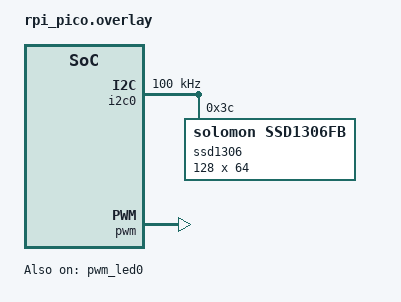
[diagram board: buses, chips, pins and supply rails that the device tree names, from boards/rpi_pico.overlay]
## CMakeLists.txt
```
# SPDX-License-Identifier: Apache-2.0

cmake_minimum_required(VERSION 3.20.0)
find_package(Zephyr REQUIRED HINTS $ENV{ZEPHYR_BASE})
project(zephyr_ssd1306)

target_sources(app PRIVATE src/main.c)
```

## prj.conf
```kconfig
CONFIG_I2C=y
CONFIG_DISPLAY=y
CONFIG_SSD1306=y
CONFIG_SSD1306_DEFAULT=y
CONFIG_SSD1306_DEFAULT_CONTRAST=128
CONFIG_LOG=y
CONFIG_CHARACTER_FRAMEBUFFER=y

CONFIG_STDOUT_CONSOLE=y

CONFIG_HEAP_MEM_POOL_SIZE=16384

CONFIG_DISPLAY=y

CONFIG_LOG=y

CONFIG_CFB_LOG_LEVEL_DBG=y
CONFIG_CHARACTER_FRAMEBUFFER=y
```

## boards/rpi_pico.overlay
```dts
#include "rpi_pico-pinctrl.dtsi"

/ {
pwm_leds {
		compatible = "pwm-leds";
		status = "disabled";
		pwm_led1: pwm_led_1 {
			pwms = <&pwm 7 PWM_MSEC(20) PWM_POLARITY_NORMAL>;
			label = "PWM_LED";
		};
	};

	aliases {
		pwm-led1 = &pwm_led1;
	};
};


&i2c0 {
	clock-frequency = <I2C_BITRATE_STANDARD>;
	status = "okay";
	pinctrl-0 = <&i2c0_default>;
	pinctrl-names = "default";

	ssd1306: ssd1306@3c {
      	       compatible = "solomon,ssd1306fb";
	       reg = <0x3c>;
	       height = <64>;
	       width = <128>;
	       segment-offset = <0>;
	       page-offset = <0>;
	       display-offset = <0>;
	       multiplex-ratio = <63>;
	       prechargep = <0x22>;
	       com-invdir;
	       segment-remap;
      };
};


&pwm_led0 {
	status = "okay";
};

&pwm {
	status = "okay";

	pinctrl-0 = <&pwm_chn_used>;

	// for pwm chanel 3 A and B

	divider-frac-3 = <15>;
	divider-int-3 = <255>;
	
	// for pwm chanel 4 A and B
	
	divider-frac-4 = <15>;
	divider-int-4 = <255>;
};
```

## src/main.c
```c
#include <stdint.h>
#include <zephyr/device.h>
#include <zephyr/kernel.h>
#include <zephyr/drivers/display.h>
#include <zephyr/logging/log.h>

#include "Logo_b.h"

#define DISPLAY_BUFFER_PITCH 128

LOG_MODULE_REGISTER(display);

static const struct device *display = DEVICE_DT_GET(DT_NODELABEL(ssd1306));

void main(void)
{
  if (display == NULL) {
    LOG_ERR("device pointer is NULL");
    return;
  }

  if (!device_is_ready(display)) {
    LOG_ERR("display device is not ready");
    return;
  }

  struct display_capabilities capabilities;
  display_get_capabilities(display, &capabilities);

  const uint16_t x_res = capabilities.x_resolution;
  const uint16_t y_res = capabilities.y_resolution;

  LOG_INF("x_resolution: %d", x_res);
  LOG_INF("y_resolution: %d", y_res);
  LOG_INF("supported pixel formats: %d", capabilities.supported_pixel_formats);
  LOG_INF("screen_info: %d", capabilities.screen_info);
  LOG_INF("current_pixel_format: %d", capabilities.current_pixel_format);
  LOG_INF("current_orientation: %d", capabilities.current_orientation);
	 
  const struct display_buffer_descriptor buf_desc = {
    .width = x_res,
    .height = y_res,
    .buf_size = x_res * y_res,
    .pitch = DISPLAY_BUFFER_PITCH
  };

  if (display_write(display, 0, 0, &buf_desc, buf) != 0) {
    LOG_ERR("could not write to display");
  }

  if (display_set_contrast(display, 0) != 0) {
    LOG_ERR("could not set display contrast");
  }
  size_t ms_sleep = 5;

  while (true) {
    // Increase brightness
    for (size_t i = 0; i < 255; i++) {
      display_set_contrast(display, i);
      k_sleep(K_MSEC(ms_sleep));
    }

    // Decrease brightness
    for (size_t i = 255; i > 0; i--) {
      display_set_contrast(display, i);
      k_sleep(K_MSEC(ms_sleep));
    }
  }
}
```

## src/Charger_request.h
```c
uint8_t buf[1024] = {
0xff, 0xff, 0xff, 0xff, 0xff, 0xff, 0xff, 0xff, 0xff, 0xff, 0xff, 0xff, 0xff, 0xff, 0xff, 0xff, 
0xff, 0xff, 0xff, 0xff, 0xff, 0xff, 0xff, 0xff, 0xff, 0xff, 0xff, 0xff, 0xff, 0xff, 0xff, 0xff, 
0xff, 0xff, 0xff, 0xff, 0xff, 0xff, 0xff, 0xff, 0xff, 0xff, 0xff, 0xff, 0xff, 0xff, 0xff, 0xff, 
0xff, 0xff, 0xff, 0xff, 0xff, 0xff, 0xff, 0xff, 0xff, 0xff, 0xff, 0xff, 0xff, 0xff, 0xff, 0xff, 
0xff, 0xff, 0xff, 0xff, 0xff, 0xff, 0xff, 0xff, 0xff, 0xff, 0xff, 0xff, 0xff, 0xff, 0xff, 0xff, 
0xff, 0xff, 0xff, 0xff, 0xff, 0xff, 0xff, 0xff, 0xff, 0xff, 0xff, 0xff, 0xff, 0xff, 0xff, 0xff, 
0xff, 0xff, 0xff, 0xff, 0xff, 0xff, 0xff, 0xff, 0xff, 0xff, 0xff, 0xff, 0xff, 0xff, 0xff, 0xff, 
0xff, 0xff, 0xff, 0xff, 0xff, 0xff, 0xff, 0xff, 0xff, 0xff, 0xff, 0xff, 0xff, 0xff, 0xff, 0xff, 
0xff, 0xff, 0xff, 0xff, 0xff, 0xff, 0xff, 0xff, 0xff, 0xff, 0xff, 0xff, 0x3f, 0x0f, 0x87, 0xe3, 
0xf3, 0xf9, 0xf9, 0xf9, 0xf9, 0xf9, 0xf9, 0xf9, 0xff, 0xff, 0xff, 0xff, 0x7f, 0x3f, 0x3f, 0x3f, 
0x3f, 0x3f, 0x7f, 0xff, 0xff, 0xff, 0xff, 0xff, 0x3f, 0x3f, 0x7f, 0x7f, 0x3f, 0x3f, 0x3f, 0x3f, 
0x7f, 0xff, 0xff, 0xff, 0xff, 0xff, 0xff, 0x7f, 0x7f, 0x3f, 0xbf, 0x3f, 0x3f, 0x7f, 0xff, 0xff, 
0xff, 0xff, 0xff, 0xff, 0x7f, 0x7f, 0x3f, 0x3f, 0x3f, 0x3f, 0x3f, 0xff, 0x3f, 0x3f, 0x07, 0x07, 
0x3f, 0x3f, 0x3f, 0xff, 0xff, 0xff, 0xff, 0xff, 0x7f, 0x3f, 0x3f, 0xbf, 0x3f, 0x7f, 0x7f, 0xff, 
0xff, 0xff, 0xff, 0xff, 0xff, 0xff, 0xff, 0xff, 0xff, 0x7f, 0x7f, 0x3f, 0xbf, 0x3f, 0x3f, 0x7f, 
0xff, 0xff, 0xff, 0xff, 0x00, 0x00, 0xff, 0xff, 0xff, 0xff, 0xff, 0xff, 0xff, 0xff, 0xff, 0xff, 
0xff, 0xff, 0xff, 0xff, 0xff, 0xff, 0xff, 0xff, 0xff, 0xff, 0xff, 0xff, 0xe0, 0x80, 0x1f, 0x3f, 
0x7f, 0xff, 0xff, 0xff, 0xff, 0xff, 0xff, 0xff, 0xff, 0xff, 0x81, 0x00, 0x3c, 0xff, 0xff, 0xff, 
0xff, 0xff, 0x3c, 0x00, 0x81, 0xff, 0xff, 0xff, 0x00, 0x00, 0xfe, 0xff, 0xff, 0xff, 0xff, 0xfe, 
0x00, 0x00, 0xff, 0xff, 0xff, 0x83, 0x00, 0x76, 0xf7, 0xf7, 0xf7, 0xf7, 0xf7, 0xf6, 0xf0, 0xf1, 
0xff, 0xff, 0x81, 0x00, 0x3c, 0x7e, 0xff, 0xff, 0xff, 0xff, 0xff, 0xff, 0xff, 0xff, 0x00, 0x00, 
0xff, 0xff, 0xff, 0xff, 0xff, 0xff, 0x83, 0x00, 0x76, 0xf7, 0xf7, 0xf7, 0xf7, 0xf6, 0xf0, 0xf1, 
0xff, 0xff, 0xff, 0xff, 0xff, 0xff, 0xff, 0x83, 0x00, 0x76, 0xf7, 0xf7, 0xf7, 0xf7, 0xf7, 0xf6, 
0xf0, 0xf1, 0xff, 0xff, 0x00, 0x00, 0xff, 0xff, 0xff, 0xff, 0xff, 0xff, 0xff, 0xff, 0xff, 0xff, 
0xff, 0xff, 0xff, 0xff, 0xff, 0xff, 0xff, 0xff, 0xff, 0xff, 0xff, 0xff, 0xff, 0xff, 0xff, 0xfe, 
0xfe, 0xfc, 0xfc, 0xfc, 0xfc, 0xfc, 0xfc, 0xfc, 0xff, 0xff, 0xff, 0xff, 0xfe, 0xfc, 0xfc, 0xfc, 
0xfc, 0xfc, 0xfe, 0xff, 0xff, 0xff, 0xff, 0xff, 0xfc, 0xfc, 0xff, 0xff, 0xff, 0xff, 0xff, 0xff, 
0xfc, 0xfc, 0xff, 0xff, 0xff, 0xff, 0xff, 0xfe, 0xfc, 0xfc, 0xfc, 0xfc, 0xfc, 0xfc, 0xfc, 0xff, 
0xff, 0xff, 0xff, 0xff, 0xfe, 0xfc, 0xfc, 0xfc, 0xfc, 0xfc, 0xfc, 0xff, 0xff, 0xff, 0xff, 0xfc, 
0xfc, 0xfc, 0xfc, 0xff, 0xff, 0xff, 0xff, 0xff, 0xfe, 0xfc, 0xfc, 0xfc, 0xfc, 0xfc, 0xfc, 0xff, 
0xff, 0xff, 0xff, 0xff, 0xff, 0xff, 0xff, 0xff, 0xff, 0xfe, 0xfc, 0xfc, 0xfc, 0xfc, 0xfc, 0xfc, 
0xfc, 0xff, 0xff, 0xff, 0xfc, 0xfc, 0xff, 0xff, 0xff, 0xff, 0xff, 0xff, 0xff, 0xff, 0xff, 0xff, 
0xff, 0xff, 0xff, 0xff, 0xff, 0xff, 0xff, 0xff, 0xff, 0xff, 0xff, 0xff, 0xff, 0xff, 0xff, 0xff, 
0xff, 0x3f, 0x0f, 0x87, 0xe3, 0xf3, 0xf9, 0xf9, 0xf9, 0xf9, 0xf9, 0xf9, 0xf9, 0xff, 0xff, 0xff, 
0x7f, 0x3f, 0x3f, 0x3f, 0x3f, 0x3f, 0x7f, 0xff, 0xff, 0xff, 0xff, 0xff, 0x3f, 0x3f, 0x7f, 0x7f, 
0x3f, 0x3f, 0xff, 0xff, 0xff, 0x7f, 0x3f, 0x3f, 0x3f, 0x3f, 0x3f, 0x7f, 0x3f, 0x3f, 0xff, 0xff, 
0xff, 0xff, 0x7f, 0x3f, 0x3f, 0x3f, 0x3f, 0x3f, 0x7f, 0xff, 0xff, 0xff, 0xff, 0xff, 0xff, 0x7f, 
0x3f, 0x3f, 0x3f, 0x3f, 0x7f, 0x7f, 0x00, 0x00, 0xff, 0xff, 0xff, 0xff, 0xff, 0x7f, 0x7f, 0x3f, 
0x3f, 0x3f, 0x3f, 0x7f, 0x7f, 0xff, 0xff, 0xff, 0xff, 0xff, 0x3f, 0x3f, 0x7f, 0x7f, 0x3f, 0x3f, 
0xff, 0xff, 0xff, 0xff, 0xff, 0xff, 0xff, 0xff, 0xff, 0xff, 0xff, 0xff, 0xff, 0xff, 0xff, 0xff, 
0xff, 0xff, 0xff, 0xff, 0xff, 0xff, 0xff, 0xff, 0xff, 0xff, 0xff, 0xff, 0xff, 0xff, 0xff, 0xff, 
0xff, 0xe0, 0x80, 0x1f, 0x3f, 0x7f, 0xff, 0xff, 0xff, 0xff, 0xff, 0xff, 0xff, 0xff, 0xff, 0x1f, 
0x0f, 0xe7, 0xf7, 0xf7, 0xf7, 0x76, 0x00, 0x00, 0xff, 0xff, 0xff, 0xff, 0x00, 0x00, 0xfc, 0xff, 
0xff, 0xff, 0xff, 0x83, 0x00, 0x3c, 0x7e, 0xff, 0xff, 0xff, 0xff, 0x7e, 0x00, 0x00, 0xff, 0xff, 
0xff, 0x1f, 0x0f, 0xe7, 0xf7, 0xf7, 0xf7, 0x76, 0x00, 0x00, 0xff, 0xff, 0xff, 0x83, 0x00, 0x3c, 
0x7e, 0xff, 0xff, 0xff, 0xff, 0x7e, 0x00, 0x00, 0xff, 0xff, 0xff, 0xc3, 0x00, 0x3c, 0x7e, 0xff, 
0xff, 0xff, 0xff, 0x7e, 0x3c, 0x00, 0xc3, 0xff, 0xff, 0xff, 0x00, 0x00, 0xfc, 0xff, 0xff, 0xff, 
0xff, 0xff, 0xff, 0xff, 0xff, 0xff, 0xff, 0xff, 0xff, 0xff, 0xff, 0xff, 0xff, 0xff, 0xff, 0xff, 
0xff, 0xff, 0xff, 0xff, 0xff, 0xff, 0xff, 0xff, 0xff, 0xff, 0xff, 0xff, 0xff, 0xff, 0xff, 0xff, 
0xff, 0xff, 0xff, 0xff, 0xfe, 0xfe, 0xfc, 0xfc, 0xfc, 0xfc, 0xfc, 0xfc, 0xfc, 0xff, 0xff, 0xfe, 
0xfe, 0xfc, 0xfc, 0xfc, 0xfe, 0xfe, 0xfc, 0xfc, 0xff, 0xff, 0xff, 0xff, 0xfc, 0xfc, 0xff, 0xff, 
0xff, 0xff, 0xff, 0xff, 0xdf, 0x9e, 0x9c, 0x9c, 0x9c, 0x9c, 0x9e, 0xce, 0xc0, 0xf0, 0xff, 0xff, 
0xff, 0xfe, 0xfe, 0xfc, 0xfc, 0xfc, 0xfe, 0xfe, 0xfc, 0xfc, 0xff, 0xff, 0xff, 0xff, 0xff, 0xfe, 
0xfc, 0xfc, 0xfc, 0xfc, 0xfe, 0xfe, 0xfc, 0xfc, 0xff, 0xff, 0xff, 0xff, 0xff, 0xfe, 0xfe, 0xfc, 
0xfc, 0xfc, 0xfc, 0xfe, 0xfe, 0xff, 0xff, 0xff, 0xff, 0xff, 0xfc, 0xfc, 0xff, 0xff, 0xff, 0xff, 
0xff, 0xff, 0xff, 0xff, 0xff, 0xff, 0xff, 0xff, 0xff, 0xff, 0xff, 0xff, 0xff, 0xff, 0xff, 0xff, 
0xff, 0xff, 0xff, 0xff, 0xff, 0xff, 0xff, 0xff, 0xff, 0xff, 0xff, 0xff, 0xff, 0xff, 0xff, 0xff, 
0xff, 0xff, 0xff, 0xff, 0xff, 0xff, 0xff, 0xff, 0xff, 0xff, 0xff, 0xff, 0xff, 0xff, 0xff, 0xff, 
0xff, 0xff, 0xff, 0xff, 0xff, 0xff, 0xff, 0xff, 0xff, 0xff, 0xff, 0xff, 0xff, 0xff, 0xff, 0xff, 
0xff, 0xff, 0xff, 0xff, 0xff, 0xff, 0xff, 0xff, 0xff, 0xff, 0xff, 0xff, 0xff, 0xff, 0xff, 0xff, 
0xff, 0xff, 0xff, 0xff, 0xff, 0xff, 0xff, 0xff, 0xff, 0xff, 0xff, 0xff, 0xff, 0xff, 0xff, 0xff, 
0xff, 0xff, 0xff, 0xff, 0xff, 0xff, 0xff, 0xff, 0xff, 0xff, 0xff, 0xff, 0xff, 0xff, 0xff, 0xff, 
0xff, 0xff, 0xff, 0xff, 0xff, 0xff, 0xff, 0xff, 0xff, 0xff, 0xff, 0xff, 0xff, 0xff, 0xff, 0xff, 
0xff, 0xff, 0xff, 0xff, 0xff, 0xff, 0xff, 0xff, 0xff, 0xff, 0xff, 0xff, 0xff, 0xff, 0xff, 0xff
};
```

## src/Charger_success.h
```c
uint8_t buf[1024] = {
0xff, 0xff, 0xff, 0xff, 0xff, 0xff, 0xff, 0xff, 0xff, 0xff, 0xff, 0xff, 0xff, 0xff, 0xff, 0xff, 
0xff, 0xff, 0xff, 0xff, 0xff, 0xff, 0xff, 0xff, 0xff, 0xff, 0xff, 0xff, 0xff, 0xff, 0xff, 0xff, 
0xff, 0xff, 0xff, 0xff, 0xff, 0xff, 0xff, 0xff, 0xff, 0xff, 0xff, 0xff, 0xff, 0xff, 0xff, 0xff, 
0xff, 0xff, 0xff, 0xff, 0xff, 0xff, 0xff, 0xff, 0xff, 0xff, 0xff, 0xff, 0xff, 0xff, 0xff, 0xff, 
0xff, 0xff, 0xff, 0xff, 0xff, 0xff, 0xff, 0xff, 0xff, 0xff, 0xff, 0xff, 0xff, 0xff, 0xff, 0xff, 
0xff, 0xff, 0xff, 0xff, 0xff, 0xff, 0xff, 0xff, 0xff, 0xff, 0xff, 0xff, 0xff, 0xff, 0xff, 0xff, 
0xff, 0xff, 0xff, 0xff, 0xff, 0xff, 0xff, 0xff, 0xff, 0xff, 0xff, 0xff, 0xff, 0xff, 0xff, 0xff, 
0xff, 0xff, 0xff, 0xff, 0xff, 0xff, 0xff, 0xff, 0xff, 0xff, 0xff, 0xff, 0xff, 0xff, 0xff, 0xff, 
0xff, 0xff, 0xff, 0xff, 0x7f, 0x1f, 0x0f, 0xc7, 0xe7, 0xf3, 0xf3, 0xf3, 0xf3, 0xf3, 0xf3, 0xf3, 
0xff, 0xff, 0xff, 0x7f, 0x7f, 0x7f, 0x7f, 0x7f, 0xff, 0xff, 0xff, 0xff, 0xff, 0xff, 0x7f, 0x7f, 
0xff, 0xff, 0x7f, 0x7f, 0xff, 0xff, 0xff, 0xff, 0xff, 0x7f, 0x7f, 0x7f, 0x7f, 0xff, 0xff, 0x7f, 
0x7f, 0xff, 0xff, 0xff, 0xff, 0x7f, 0x7f, 0x7f, 0x7f, 0x7f, 0xff, 0xff, 0xff, 0xff, 0xff, 0xff, 
0xff, 0xff, 0xff, 0x7f, 0x7f, 0x7f, 0x7f, 0xff, 0xff, 0x01, 0x01, 0xff, 0xff, 0xff, 0xff, 0xff, 
0xff, 0x7f, 0x7f, 0x7f, 0x7f, 0x7f, 0xff, 0xff, 0xff, 0xff, 0xff, 0xff, 0x7f, 0x7f, 0xff, 0xff, 
0x7f, 0x7f, 0xff, 0xff, 0xff, 0xff, 0xff, 0xff, 0xff, 0xff, 0xff, 0xff, 0xff, 0xff, 0xff, 0xff, 
0xff, 0xff, 0xff, 0xff, 0xff, 0x7f, 0x3f, 0x1f, 0x0f, 0x0f, 0x9f, 0xff, 0xff, 0xff, 0xff, 0xff, 
0xff, 0xff, 0xff, 0xff, 0xc0, 0x00, 0x3f, 0x7f, 0xff, 0xff, 0xff, 0xff, 0xff, 0xff, 0xff, 0xff, 
0xff, 0x3f, 0x1e, 0xce, 0xce, 0xee, 0xee, 0xee, 0xe4, 0x00, 0x01, 0xff, 0xff, 0xff, 0x00, 0x00, 
0xf9, 0xfc, 0xfe, 0xfe, 0xff, 0xff, 0x03, 0x01, 0x78, 0xfe, 0xfe, 0xfe, 0xfe, 0xfe, 0x7c, 0x00, 
0x00, 0xff, 0xff, 0x3f, 0x1e, 0xce, 0xce, 0xee, 0xee, 0xee, 0xe4, 0x00, 0x01, 0xff, 0xff, 0xff, 
0x03, 0x01, 0xf8, 0xfe, 0xfe, 0xfe, 0xfe, 0xfe, 0xf8, 0x00, 0x00, 0xff, 0xff, 0xff, 0x03, 0x01, 
0x78, 0xfe, 0xfe, 0xfe, 0xfe, 0xfe, 0x78, 0x01, 0x03, 0xff, 0xff, 0xff, 0x00, 0x00, 0xf9, 0xfc, 
0xfe, 0xfe, 0xff, 0xff, 0xff, 0xff, 0xff, 0xff, 0xe7, 0xc3, 0x83, 0x03, 0x07, 0x0f, 0x1f, 0x1f, 
0x0f, 0x07, 0x83, 0xc1, 0xe0, 0xf0, 0xf8, 0xfc, 0xfe, 0xff, 0xff, 0xff, 0xff, 0xff, 0xff, 0xff, 
0xff, 0xff, 0xff, 0xff, 0xff, 0xff, 0xfe, 0xfc, 0xfc, 0xf9, 0xf9, 0xf9, 0xf9, 0xf9, 0xf9, 0xf9, 
0xff, 0xfe, 0xfc, 0xf8, 0xf9, 0xf9, 0xf9, 0xfd, 0xfc, 0xf8, 0xf8, 0xff, 0xff, 0xff, 0xf8, 0xf8, 
0xff, 0xff, 0xff, 0xff, 0xff, 0xff, 0xff, 0xbc, 0x3c, 0x39, 0x39, 0x39, 0x39, 0x3d, 0x8c, 0xc0, 
0xe0, 0xff, 0xff, 0xfe, 0xfc, 0xf8, 0xf9, 0xf9, 0xf9, 0xfd, 0xfc, 0xf8, 0xf8, 0xff, 0xff, 0xff, 
0xff, 0xfc, 0xfc, 0xf9, 0xf9, 0xf9, 0xf9, 0xfd, 0xfe, 0xf8, 0xf8, 0xff, 0xff, 0xff, 0xff, 0xfe, 
0xfc, 0xf9, 0xf9, 0xf9, 0xf9, 0xf9, 0xfc, 0xfe, 0xff, 0xff, 0xff, 0xff, 0xf8, 0xf8, 0xff, 0xff, 
0xff, 0xff, 0xff, 0xff, 0xff, 0xff, 0xff, 0xff, 0xff, 0xff, 0xff, 0xff, 0xfe, 0xfc, 0xf8, 0xfc, 
0xfe, 0xff, 0xff, 0xff, 0xff, 0xff, 0xff, 0xff, 0xff, 0xff, 0xff, 0xff, 0xff, 0xff, 0xff, 0xff, 
0xff, 0xff, 0xff, 0xff, 0xff, 0x7f, 0x3f, 0x1f, 0x9f, 0xcf, 0xcf, 0xcf, 0xcf, 0xcf, 0xcf, 0xcf, 
0xff, 0xff, 0xff, 0xff, 0xff, 0xff, 0xff, 0xff, 0xff, 0xff, 0xff, 0xff, 0xff, 0xff, 0xff, 0xff, 
0xff, 0xff, 0xff, 0xff, 0xff, 0xff, 0xff, 0xff, 0xff, 0xff, 0xff, 0xff, 0xff, 0xff, 0xff, 0xff, 
0xff, 0xff, 0xff, 0xff, 0xff, 0xff, 0xff, 0xff, 0xff, 0xff, 0xff, 0xff, 0xff, 0xff, 0xff, 0xff, 
0xff, 0xff, 0xff, 0xff, 0xff, 0xff, 0xff, 0x3f, 0x3f, 0xff, 0xff, 0xff, 0xff, 0xff, 0xff, 0xff, 
0xff, 0xff, 0xff, 0xff, 0xff, 0xff, 0xff, 0xff, 0xff, 0xff, 0xff, 0xff, 0xff, 0xff, 0xff, 0xff, 
0xff, 0xff, 0xff, 0x07, 0x07, 0xff, 0xff, 0xff, 0xff, 0xff, 0xff, 0xff, 0xff, 0xff, 0xff, 0xff, 
0xff, 0xff, 0xff, 0xff, 0xff, 0xff, 0xff, 0xff, 0xff, 0xff, 0xff, 0xff, 0xff, 0xff, 0xff, 0xff, 
0xff, 0xff, 0xff, 0xff, 0x01, 0x00, 0xfc, 0xff, 0xff, 0xff, 0xff, 0xff, 0xff, 0xff, 0xff, 0xff, 
0xff, 0xff, 0x0f, 0x07, 0xe3, 0xf9, 0xf9, 0xf9, 0xf9, 0xf9, 0xe3, 0x07, 0x0f, 0xff, 0xff, 0xff, 
0x01, 0x01, 0xe7, 0xfb, 0xf9, 0xf9, 0xf9, 0xf9, 0xe1, 0x03, 0x0f, 0xff, 0xff, 0x1f, 0x07, 0xb3, 
0xbb, 0xb9, 0xbd, 0xb9, 0xb9, 0xb3, 0x87, 0x8f, 0xff, 0xff, 0x1f, 0x07, 0xe3, 0xf3, 0xf9, 0xf9, 
0xf9, 0xf9, 0xf9, 0xff, 0xff, 0xf9, 0xf9, 0x00, 0x00, 0xf9, 0xf9, 0xf9, 0xff, 0xff, 0x7b, 0x39, 
0x39, 0xb9, 0xb9, 0xb9, 0x93, 0x03, 0x07, 0xff, 0xff, 0xff, 0x0f, 0x07, 0xe3, 0xf9, 0xf9, 0xf9, 
0xf9, 0xfb, 0xe3, 0x00, 0x00, 0xff, 0xff, 0xff, 0x0f, 0x07, 0xe3, 0xf9, 0xf9, 0xf9, 0xf9, 0xf9, 
0xe3, 0x07, 0x0f, 0xff, 0xff, 0xff, 0xff, 0xff, 0xff, 0xff, 0xff, 0xff, 0xff, 0xff, 0xff, 0xff, 
0xff, 0xff, 0xff, 0xff, 0xff, 0xfc, 0xf8, 0xf1, 0xf3, 0xe7, 0xe7, 0xe7, 0xe7, 0xe7, 0xe7, 0xe7, 
0xff, 0xff, 0xfc, 0xf8, 0xf1, 0xe7, 0xe7, 0xe7, 0xe7, 0xe7, 0xf1, 0xf8, 0xfc, 0xff, 0xff, 0xff, 
0xe0, 0xe0, 0xff, 0xff, 0xff, 0xff, 0xff, 0xff, 0xff, 0xe0, 0xe0, 0xff, 0xff, 0xfc, 0xf8, 0xf3, 
0xe7, 0xe7, 0xe7, 0xe7, 0xe7, 0xe7, 0xe7, 0xff, 0xff, 0xff, 0xfe, 0xf8, 0xf1, 0xf3, 0xe7, 0xe7, 
0xe7, 0xe7, 0xe7, 0xff, 0xff, 0xff, 0xff, 0xf0, 0xe0, 0xe7, 0xe7, 0xe7, 0xff, 0xf8, 0xf0, 0xe3, 
0xe7, 0xe7, 0xe7, 0xf7, 0xf3, 0xe0, 0xe0, 0xff, 0xff, 0xff, 0xfc, 0xf0, 0xf3, 0xe7, 0xe7, 0xe7, 
0xe7, 0xf7, 0xfb, 0xe0, 0xe0, 0xff, 0xff, 0xff, 0xfc, 0xf8, 0xf1, 0xe7, 0xe7, 0xe7, 0xe7, 0xe7, 
0xf1, 0xf8, 0xfc, 0xff, 0xff, 0xff, 0xff, 0xff, 0xff, 0xff, 0xff, 0xff, 0xff, 0xff, 0xff, 0xff, 
0xff, 0xff, 0xff, 0xff, 0xff, 0xff, 0xff, 0xff, 0xff, 0xff, 0xff, 0xff, 0xff, 0xff, 0xff, 0xff, 
0xff, 0xff, 0xff, 0xff, 0xff, 0xff, 0xff, 0xff, 0xff, 0xff, 0xff, 0xff, 0xff, 0xff, 0xff, 0xff, 
0xff, 0xff, 0xff, 0xff, 0xff, 0xff, 0xff, 0xff, 0xff, 0xff, 0xff, 0xff, 0xff, 0xff, 0xff, 0xff, 
0xff, 0xff, 0xff, 0xff, 0xff, 0xff, 0xff, 0xff, 0xff, 0xff, 0xff, 0xff, 0xff, 0xff, 0xff, 0xff, 
0xff, 0xff, 0xff, 0xff, 0xff, 0xff, 0xff, 0xff, 0xff, 0xff, 0xff, 0xff, 0xff, 0xff, 0xff, 0xff, 
0xff, 0xff, 0xff, 0xff, 0xff, 0xff, 0xff, 0xff, 0xff, 0xff, 0xff, 0xff, 0xff, 0xff, 0xff, 0xff, 
0xff, 0xff, 0xff, 0xff, 0xff, 0xff, 0xff, 0xff, 0xff, 0xff, 0xff, 0xff, 0xff, 0xff, 0xff, 0xff, 
0xff, 0xff, 0xff, 0xff, 0xff, 0xff, 0xff, 0xff, 0xff, 0xff, 0xff, 0xff, 0xff, 0xff, 0xff, 0xff
};
```

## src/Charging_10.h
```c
uint8_t buf[1024] = {
0xff, 0xff, 0xff, 0xff, 0xff, 0xff, 0xff, 0xff, 0xff, 0xff, 0xff, 0xff, 0xff, 0xff, 0xff, 0xff, 
0xff, 0x7f, 0x7f, 0x7f, 0x7f, 0x7f, 0x7f, 0x7f, 0xff, 0xff, 0xff, 0xff, 0xff, 0xff, 0xff, 0xff, 
0xff, 0xff, 0xff, 0xff, 0xff, 0xff, 0xff, 0xff, 0xff, 0xff, 0xff, 0xff, 0xff, 0xff, 0xff, 0xff, 
0xff, 0xff, 0xff, 0xff, 0xff, 0xff, 0xff, 0xff, 0xff, 0xff, 0xff, 0xff, 0xff, 0xff, 0xff, 0xff, 
0xff, 0xff, 0xff, 0xff, 0xff, 0xff, 0xff, 0xff, 0xff, 0xff, 0xff, 0xff, 0xff, 0xff, 0xff, 0xff, 
0xff, 0xff, 0xff, 0xff, 0xff, 0xff, 0xff, 0xff, 0xff, 0xff, 0xff, 0xff, 0xff, 0xff, 0xff, 0x3f, 
0x3f, 0xff, 0xff, 0xff, 0xff, 0xff, 0xff, 0xff, 0xff, 0xff, 0xff, 0xff, 0xff, 0xff, 0xff, 0xff, 
0xff, 0xff, 0xff, 0xff, 0xff, 0xff, 0xff, 0xff, 0xff, 0xff, 0xff, 0xff, 0xff, 0xff, 0xff, 0xff, 
0xff, 0xff, 0xff, 0xff, 0xff, 0xff, 0xff, 0xff, 0xff, 0xff, 0xff, 0xff, 0x0f, 0x03, 0xe1, 0xf8, 
0xfc, 0xfe, 0xfe, 0xfe, 0xfe, 0xfe, 0xfe, 0xfe, 0xff, 0xff, 0xdf, 0xcf, 0xcf, 0xcf, 0xcf, 0xcf, 
0x9f, 0x1f, 0x3f, 0xff, 0xff, 0xff, 0x0f, 0x0f, 0x3f, 0x9f, 0xcf, 0xcf, 0xff, 0xff, 0x7f, 0x3f, 
0x1f, 0xcf, 0xcf, 0xcf, 0xcf, 0xdf, 0x9f, 0x0f, 0x0f, 0xff, 0xff, 0xff, 0xdf, 0xcf, 0xcf, 0xcf, 
0xcf, 0xcf, 0x9f, 0x1f, 0x3f, 0xff, 0xff, 0xff, 0x0f, 0x0f, 0x3f, 0xdf, 0xcf, 0xcf, 0xcf, 0xcf, 
0x0f, 0x1f, 0x7f, 0xff, 0xff, 0xff, 0x7f, 0x3f, 0x1f, 0xcf, 0xcf, 0xcf, 0xcf, 0xdf, 0x1f, 0x00, 
0x00, 0xff, 0xff, 0xff, 0x7f, 0x3f, 0x1f, 0xcf, 0xcf, 0xcf, 0xcf, 0xcf, 0x1f, 0x3f, 0x7f, 0xff, 
0xff, 0xff, 0xff, 0xff, 0xff, 0xff, 0xff, 0xff, 0xff, 0xff, 0xff, 0xff, 0xff, 0xff, 0xff, 0xff, 
0xff, 0xff, 0xff, 0xff, 0xff, 0xff, 0xff, 0xff, 0xff, 0xff, 0xff, 0xff, 0xf8, 0xe0, 0xc7, 0x8f, 
0x9f, 0x3f, 0x3f, 0x3f, 0x3f, 0x3f, 0x3f, 0x3f, 0xff, 0xc7, 0x83, 0x19, 0x39, 0x3d, 0x3d, 0xbd, 
0x9c, 0x00, 0x00, 0xff, 0xff, 0xff, 0x00, 0x00, 0xff, 0xff, 0xff, 0xff, 0xff, 0xff, 0xe0, 0x80, 
0x8f, 0x3f, 0x3f, 0x3f, 0x3f, 0xbf, 0x8f, 0x00, 0x00, 0xff, 0xff, 0xc7, 0x83, 0x19, 0x39, 0x3d, 
0x3d, 0xbd, 0x9c, 0x00, 0x00, 0xff, 0xff, 0xff, 0x00, 0x00, 0xff, 0xff, 0xff, 0xff, 0xff, 0xff, 
0xff, 0x00, 0x00, 0xff, 0xff, 0xff, 0xe0, 0x80, 0x9f, 0x3f, 0x3f, 0x3f, 0x3f, 0xbf, 0xdf, 0x00, 
0x00, 0xff, 0xff, 0xff, 0xe0, 0xc0, 0x8f, 0x3f, 0x3f, 0x3f, 0x3f, 0x3f, 0x8f, 0xc0, 0xe0, 0xff, 
0xff, 0xff, 0xff, 0xff, 0xff, 0xff, 0xff, 0xff, 0xff, 0xff, 0xff, 0xff, 0xff, 0xff, 0xff, 0xff, 
0xff, 0xff, 0xff, 0xff, 0xff, 0xff, 0xff, 0xff, 0xff, 0xff, 0xff, 0xff, 0xff, 0xff, 0xff, 0xff, 
0xff, 0xff, 0xff, 0xff, 0xff, 0xff, 0xff, 0xff, 0xff, 0xff, 0xff, 0xff, 0xff, 0xff, 0xff, 0xff, 
0xff, 0xff, 0xff, 0xff, 0xff, 0xff, 0xff, 0xff, 0xff, 0xff, 0xff, 0xff, 0xff, 0xff, 0xff, 0xf7, 
0xe7, 0xe7, 0xe7, 0xe7, 0xe7, 0xe7, 0xf1, 0xf8, 0xfc, 0xff, 0xff, 0xff, 0xff, 0xff, 0xff, 0xff, 
0xff, 0xff, 0xff, 0xff, 0xff, 0xff, 0xff, 0xff, 0xff, 0xff, 0xff, 0xff, 0xff, 0xff, 0xff, 0xff, 
0xff, 0xff, 0xff, 0xff, 0xff, 0xff, 0xff, 0xff, 0xff, 0xff, 0xff, 0xff, 0xff, 0xff, 0xff, 0xff, 
0xff, 0xff, 0xff, 0xff, 0xff, 0xff, 0xff, 0xff, 0xff, 0xff, 0xff, 0xff, 0xff, 0xff, 0xff, 0xff, 
0xff, 0xff, 0xff, 0xff, 0xff, 0xff, 0xff, 0xff, 0xff, 0xff, 0xff, 0xff, 0xff, 0xff, 0xff, 0xff, 
0xff, 0xff, 0xff, 0xff, 0xff, 0xff, 0xff, 0xff, 0xff, 0xff, 0xff, 0xff, 0xff, 0xff, 0xff, 0xff, 
0x3f, 0x1f, 0x0f, 0x07, 0x03, 0x83, 0xc1, 0xe1, 0xe1, 0xe1, 0xf1, 0xf1, 0xf0, 0xf0, 0xf0, 0xf0, 
0xf0, 0xf0, 0xf0, 0xf0, 0xf0, 0xf0, 0xf0, 0xf0, 0xf0, 0xf0, 0xf0, 0xf0, 0xf0, 0xf0, 0xf0, 0xf0, 
0xf0, 0xf0, 0xf0, 0xf0, 0xf0, 0xf0, 0xf0, 0xf0, 0xf0, 0xf0, 0xf0, 0xf0, 0xf0, 0xf0, 0xf0, 0xf0, 
0xf0, 0xf0, 0xf0, 0xf0, 0xf0, 0xf0, 0xf0, 0xf0, 0xf0, 0xf0, 0xf0, 0xf0, 0xf0, 0xf0, 0xf0, 0xf0, 
0xf0, 0xf0, 0xf0, 0xf0, 0xf0, 0xf0, 0xf0, 0xf0, 0xf0, 0xf0, 0xf0, 0xf0, 0xf0, 0xf0, 0xf0, 0xf0, 
0xf0, 0xf0, 0xf0, 0xf0, 0xf0, 0xf0, 0xe0, 0xe0, 0xe1, 0xc1, 0x81, 0x03, 0x07, 0x07, 0x1f, 0x3f, 
0x7f, 0xff, 0xff, 0xff, 0xff, 0xff, 0xff, 0xff, 0xff, 0xff, 0xff, 0xff, 0xff, 0xff, 0xff, 0xff, 
0xff, 0xff, 0xff, 0xff, 0xff, 0xff, 0xff, 0xff, 0xff, 0xff, 0xff, 0xff, 0xff, 0xff, 0x87, 0x00, 
0x00, 0x00, 0x00, 0xfe, 0xff, 0xff, 0xff, 0x87, 0x03, 0x01, 0x01, 0x01, 0x01, 0x01, 0x01, 0x01, 
0xff, 0xff, 0xff, 0xff, 0xff, 0xff, 0xff, 0xff, 0xff, 0xff, 0xff, 0xff, 0xff, 0xff, 0xff, 0xff, 
0xff, 0xff, 0xff, 0xff, 0xff, 0xff, 0xff, 0xff, 0xff, 0xff, 0xff, 0xff, 0xff, 0xff, 0xff, 0xff, 
0xff, 0xff, 0xff, 0xff, 0xff, 0xff, 0xff, 0xff, 0xff, 0xff, 0xff, 0xff, 0xff, 0xff, 0xff, 0xff, 
0xff, 0xff, 0xff, 0xff, 0xff, 0xff, 0xff, 0xff, 0xff, 0xff, 0xff, 0xff, 0xff, 0xff, 0xff, 0xff, 
0xff, 0xff, 0xff, 0xff, 0xff, 0xff, 0xff, 0xff, 0xff, 0xff, 0xff, 0xff, 0xfe, 0x00, 0x00, 0x00, 
0x00, 0x03, 0xff, 0xff, 0xff, 0xff, 0xff, 0xff, 0xff, 0xff, 0xff, 0xff, 0xff, 0xff, 0xff, 0xff, 
0xff, 0xff, 0xff, 0xff, 0xff, 0xff, 0xff, 0xff, 0xff, 0xff, 0xff, 0xff, 0xff, 0xff, 0xff, 0xfc, 
0xf0, 0xc0, 0x80, 0x81, 0x03, 0x07, 0x0f, 0x1f, 0x1f, 0x1e, 0x3e, 0x3e, 0x3e, 0x3e, 0x3e, 0x3e, 
0x3f, 0x3f, 0x3f, 0x3f, 0x3f, 0x3f, 0x3f, 0x3f, 0x3f, 0x3f, 0x3f, 0x3f, 0x3f, 0x3f, 0x3f, 0x3f, 
0x3f, 0x3f, 0x3f, 0x3f, 0x3f, 0x3f, 0x3f, 0x3f, 0x3f, 0x3f, 0x3f, 0x3f, 0x3f, 0x3f, 0x3f, 0x3f, 
0x3f, 0x3f, 0x3f, 0x3f, 0x3f, 0x3f, 0x3f, 0x3f, 0x3f, 0x3f, 0x3f, 0x3f, 0x3f, 0x3f, 0x3f, 0x3f, 
0x3f, 0x3f, 0x3f, 0x3f, 0x3f, 0x3f, 0x3f, 0x3f, 0x3f, 0x3f, 0x3f, 0x3f, 0x3f, 0x3f, 0x3f, 0x3f, 
0x3f, 0x3f, 0x3f, 0x3f, 0x3f, 0x3f, 0x3f, 0x1f, 0x1f, 0x0f, 0x0f, 0x07, 0x01, 0x80, 0xc0, 0xe0, 
0xf8, 0xff, 0xff, 0xff, 0xff, 0xff, 0xff, 0xff, 0xff, 0xff, 0xff, 0xff, 0xff, 0xff, 0xff, 0xff, 
0xff, 0xff, 0xff, 0xff, 0xff, 0xff, 0xff, 0xff, 0xff, 0xff, 0xff, 0xff, 0xff, 0xff, 0xff, 0xff, 
0xff, 0xff, 0xff, 0xff, 0xff, 0xfe, 0xfe, 0xfc, 0xfc, 0xfc, 0xfc, 0xfc, 0xfc, 0xfc, 0xfc, 0xfc, 
0xfc, 0xfc, 0xfc, 0xfc, 0xfc, 0xfc, 0xfc, 0xfc, 0xfc, 0xfc, 0xfc, 0xfc, 0xfc, 0xfc, 0xfc, 0xfc, 
0xfc, 0xfc, 0xfc, 0xfc, 0xfc, 0xfc, 0xfc, 0xfc, 0xfc, 0xfc, 0xfc, 0xfc, 0xfc, 0xfc, 0xfc, 0xfc, 
0xfc, 0xfc, 0xfc, 0xfc, 0xfc, 0xfc, 0xfc, 0xfc, 0xfc, 0xfc, 0xfc, 0xfc, 0xfc, 0xfc, 0xfc, 0xfc, 
0xfc, 0xfc, 0xfc, 0xfc, 0xfc, 0xfc, 0xfc, 0xfc, 0xfc, 0xfc, 0xfc, 0xfc, 0xfc, 0xfc, 0xfc, 0xfc, 
0xfc, 0xfc, 0xfc, 0xfc, 0xfc, 0xfc, 0xfc, 0xfc, 0xfc, 0xfe, 0xfe, 0xff, 0xff, 0xff, 0xff, 0xff, 
0xff, 0xff, 0xff, 0xff, 0xff, 0xff, 0xff, 0xff, 0xff, 0xff, 0xff, 0xff, 0xff, 0xff, 0xff, 0xff
};
```

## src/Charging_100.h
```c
uint8_t buf[1024] = {
    0xff, 0xff, 0xff, 0xff, 0xff, 0xff, 0xff, 0xff, 0xff, 0xff, 0xff, 0xff, 0xff, 0xff, 0xff, 0xff, 
	0xff, 0xff, 0xff, 0xff, 0xff, 0xff, 0xff, 0xff, 0xff, 0xff, 0xff, 0x7f, 0x7f, 0x7f, 0x7f, 0x7f, 
	0x7f, 0x7f, 0xff, 0xff, 0xff, 0xff, 0xff, 0xff, 0xff, 0xff, 0xff, 0xff, 0xff, 0xff, 0xff, 0xff, 
	0xff, 0xff, 0xff, 0xff, 0xff, 0xff, 0xff, 0xff, 0xff, 0xff, 0xff, 0xff, 0xff, 0xff, 0xff, 0xff, 
	0xff, 0xff, 0xff, 0xff, 0xff, 0xff, 0xff, 0xff, 0xff, 0xff, 0xff, 0xff, 0xff, 0xff, 0xff, 0xff, 
	0xff, 0xff, 0xff, 0xff, 0xff, 0xff, 0xff, 0xff, 0xff, 0xff, 0xff, 0x3f, 0x3f, 0xff, 0xff, 0xff, 
	0xff, 0xff, 0xff, 0xff, 0xff, 0xff, 0xff, 0xff, 0xff, 0xff, 0xff, 0xff, 0xff, 0xff, 0xff, 0xff, 
	0xff, 0xff, 0xff, 0xff, 0xff, 0xff, 0xff, 0xff, 0xff, 0xff, 0xff, 0xff, 0xff, 0xff, 0xff, 0xff, 
	0xff, 0xff, 0xff, 0xff, 0xff, 0xff, 0xff, 0xff, 0xff, 0xff, 0xff, 0xff, 0xff, 0xff, 0xff, 0xff, 
	0xff, 0xff, 0xff, 0xff, 0xff, 0xff, 0x0f, 0x03, 0xe1, 0xf8, 0xfc, 0xfe, 0xfe, 0xfe, 0xfe, 0xfe, 
	0xfe, 0xfe, 0xff, 0xff, 0xdf, 0xcf, 0xcf, 0xcf, 0xcf, 0xcf, 0x9f, 0x1f, 0x3f, 0xff, 0xff, 0xff, 
	0x0f, 0x0f, 0x3f, 0x9f, 0xcf, 0xcf, 0xff, 0xff, 0x7f, 0x3f, 0x1f, 0xcf, 0xcf, 0xcf, 0xcf, 0xdf, 
	0x9f, 0x0f, 0x0f, 0xff, 0xff, 0xff, 0xdf, 0xcf, 0xcf, 0xcf, 0xcf, 0xcf, 0x9f, 0x1f, 0x3f, 0xff, 
	0xff, 0xff, 0x7f, 0x3f, 0x1f, 0xcf, 0xcf, 0xcf, 0xcf, 0xdf, 0x1f, 0x00, 0x00, 0xff, 0xff, 0xff, 
	0x7f, 0x3f, 0x1f, 0xcf, 0xcf, 0xcf, 0xcf, 0xcf, 0x1f, 0x3f, 0x7f, 0xff, 0xff, 0xff, 0xff, 0xff, 
	0xff, 0xff, 0xff, 0xff, 0xff, 0xff, 0xff, 0xff, 0xff, 0xff, 0xff, 0xff, 0xff, 0xff, 0xff, 0xff, 
	0xff, 0xff, 0xff, 0xff, 0xff, 0xff, 0xff, 0xff, 0xff, 0xff, 0xff, 0xff, 0xff, 0xff, 0xff, 0xff, 
	0xff, 0xff, 0xff, 0xff, 0xff, 0xff, 0xf8, 0xe0, 0xc7, 0x8f, 0x9f, 0x3f, 0x3f, 0x3f, 0x3f, 0x3f, 
	0x3f, 0x3f, 0xff, 0xc7, 0x83, 0x19, 0x39, 0x3d, 0x3d, 0xbd, 0x9c, 0x00, 0x00, 0xff, 0xff, 0xff, 
	0x00, 0x00, 0xff, 0xff, 0xff, 0xff, 0xff, 0xff, 0xe0, 0x80, 0x8f, 0x3f, 0x3f, 0x3f, 0x3f, 0xbf, 
	0x8f, 0x00, 0x00, 0xff, 0xff, 0xc7, 0x83, 0x19, 0x39, 0x3d, 0x3d, 0xbd, 0x9c, 0x00, 0x00, 0xff, 
	0xff, 0xff, 0xe0, 0x80, 0x9f, 0x3f, 0x3f, 0x3f, 0x3f, 0xbf, 0xdf, 0x00, 0x00, 0xff, 0xff, 0xff, 
	0xe0, 0xc0, 0x8f, 0x3f, 0x3f, 0x3f, 0x3f, 0x3f, 0x8f, 0xc0, 0xe0, 0xff, 0xff, 0xff, 0xff, 0xff, 
	0xff, 0xff, 0xff, 0xff, 0xff, 0xff, 0xff, 0xff, 0xff, 0xff, 0xff, 0xff, 0xff, 0xff, 0xff, 0xff, 
	0xff, 0xff, 0xff, 0xff, 0xff, 0xff, 0xff, 0xff, 0xff, 0xff, 0xff, 0xff, 0xff, 0xff, 0xff, 0xff, 
	0xff, 0xff, 0xff, 0xff, 0xff, 0xff, 0xff, 0xff, 0xff, 0xff, 0xff, 0xff, 0xff, 0xff, 0xff, 0xff, 
	0xff, 0xff, 0xff, 0xff, 0xff, 0xff, 0xff, 0xff, 0xff, 0xff, 0xff, 0xff, 0xff, 0xff, 0xff, 0xff, 
	0xff, 0xff, 0xff, 0xff, 0xff, 0xff, 0xff, 0xff, 0xff, 0xf7, 0xe7, 0xe7, 0xe7, 0xe7, 0xe7, 0xe7, 
	0xf1, 0xf8, 0xfc, 0xff, 0xff, 0xff, 0xff, 0xff, 0xff, 0xff, 0xff, 0xff, 0xff, 0xff, 0xff, 0xff, 
	0xff, 0xff, 0xff, 0xff, 0xff, 0xff, 0xff, 0xff, 0xff, 0xff, 0xff, 0xff, 0xff, 0xff, 0xff, 0xff, 
	0xff, 0xff, 0xff, 0xff, 0xff, 0xff, 0xff, 0xff, 0xff, 0xff, 0xff, 0xff, 0xff, 0xff, 0xff, 0xff, 
	0xff, 0xff, 0xff, 0xff, 0xff, 0xff, 0xff, 0xff, 0xff, 0xff, 0xff, 0xff, 0xff, 0xff, 0xff, 0xff, 
	0xff, 0xff, 0xff, 0xff, 0xff, 0xff, 0xff, 0xff, 0xff, 0xff, 0xff, 0xff, 0xff, 0xff, 0xff, 0xff, 
	0x3f, 0x1f, 0x0f, 0x07, 0x03, 0x83, 0xc1, 0xe1, 0xe1, 0xe1, 0xf1, 0xf1, 0xf0, 0xf0, 0xf0, 0xf0, 
	0xf0, 0xf0, 0xf0, 0xf0, 0xf0, 0xf0, 0xf0, 0xf0, 0xf0, 0xf0, 0xf0, 0xf0, 0xf0, 0xf0, 0xf0, 0xf0, 
	0xf0, 0xf0, 0xf0, 0xf0, 0xf0, 0xf0, 0xf0, 0xf0, 0xf0, 0xf0, 0xf0, 0xf0, 0xf0, 0xf0, 0xf0, 0xf0, 
	0xf0, 0xf0, 0xf0, 0xf0, 0xf0, 0xf0, 0xf0, 0xf0, 0xf0, 0xf0, 0xf0, 0xf0, 0xf0, 0xf0, 0xf0, 0xf0, 
	0xf0, 0xf0, 0xf0, 0xf0, 0xf0, 0xf0, 0xf0, 0xf0, 0xf0, 0xf0, 0xf0, 0xf0, 0xf0, 0xf0, 0xf0, 0xf0, 
	0xf0, 0xf0, 0xf0, 0xf0, 0xf0, 0xf0, 0xe0, 0xe0, 0xe1, 0xc1, 0x81, 0x03, 0x07, 0x07, 0x1f, 0x3f, 
	0x7f, 0xff, 0xff, 0xff, 0xff, 0xff, 0xff, 0xff, 0xff, 0xff, 0xff, 0xff, 0xff, 0xff, 0xff, 0xff, 
	0xff, 0xff, 0xff, 0xff, 0xff, 0xff, 0xff, 0xff, 0xff, 0xff, 0xff, 0xff, 0xff, 0xff, 0x87, 0x00, 
	0x00, 0x00, 0x00, 0xfe, 0xff, 0xff, 0xff, 0x87, 0x03, 0x01, 0x01, 0x01, 0x01, 0x01, 0x01, 0x01, 
	0x01, 0x01, 0x01, 0x01, 0x01, 0x01, 0x01, 0x01, 0x01, 0x01, 0x01, 0x01, 0x01, 0x01, 0x01, 0x01, 
	0x01, 0x01, 0x01, 0x01, 0x01, 0x01, 0x01, 0x01, 0x01, 0x01, 0x01, 0x01, 0x01, 0x01, 0x01, 0x01, 
	0x01, 0x01, 0x01, 0x01, 0x01, 0x01, 0x01, 0x01, 0x01, 0x01, 0x01, 0x01, 0x01, 0x01, 0x01, 0x01, 
	0x01, 0x01, 0x01, 0x01, 0x01, 0x01, 0x01, 0x01, 0x01, 0x01, 0x01, 0x01, 0x01, 0x01, 0x01, 0x01, 
	0x01, 0x01, 0x01, 0x01, 0x01, 0x01, 0x01, 0x03, 0x87, 0xff, 0xff, 0xff, 0xfe, 0x00, 0x00, 0x00, 
	0x00, 0x03, 0xff, 0xff, 0xff, 0xff, 0xff, 0xff, 0xff, 0xff, 0xff, 0xff, 0xff, 0xff, 0xff, 0xff, 
	0xff, 0xff, 0xff, 0xff, 0xff, 0xff, 0xff, 0xff, 0xff, 0xff, 0xff, 0xff, 0xff, 0xff, 0xff, 0xfc, 
	0xf0, 0xc0, 0x80, 0x81, 0x03, 0x07, 0x0f, 0x1f, 0x1f, 0x1e, 0x3e, 0x3e, 0x3e, 0x3e, 0x3e, 0x3e, 
	0x3e, 0x3e, 0x3e, 0x3e, 0x3e, 0x3e, 0x3e, 0x3e, 0x3e, 0x3e, 0x3e, 0x3e, 0x3e, 0x3e, 0x3e, 0x3e, 
	0x3e, 0x3e, 0x3e, 0x3e, 0x3e, 0x3e, 0x3e, 0x3e, 0x3e, 0x3e, 0x3e, 0x3e, 0x3e, 0x3e, 0x3c, 0x3e, 
	0x3e, 0x3e, 0x3e, 0x3e, 0x3e, 0x3e, 0x3e, 0x3e, 0x3e, 0x3e, 0x3e, 0x3e, 0x3e, 0x3e, 0x3e, 0x3e, 
	0x3e, 0x3e, 0x3e, 0x3e, 0x3e, 0x3e, 0x3e, 0x3e, 0x3e, 0x3e, 0x3e, 0x3e, 0x3e, 0x3e, 0x3e, 0x3e, 
	0x3e, 0x3e, 0x3e, 0x3e, 0x3e, 0x3e, 0x3e, 0x1f, 0x1f, 0x0f, 0x0f, 0x07, 0x01, 0x80, 0xc0, 0xe0, 
	0xf8, 0xff, 0xff, 0xff, 0xff, 0xff, 0xff, 0xff, 0xff, 0xff, 0xff, 0xff, 0xff, 0xff, 0xff, 0xff, 
	0xff, 0xff, 0xff, 0xff, 0xff, 0xff, 0xff, 0xff, 0xff, 0xff, 0xff, 0xff, 0xff, 0xff, 0xff, 0xff, 
	0xff, 0xff, 0xff, 0xff, 0xff, 0xfe, 0xfe, 0xfc, 0xfc, 0xfc, 0xfc, 0xfc, 0xfc, 0xfc, 0xfc, 0xfc, 
	0xfc, 0xfc, 0xfc, 0xfc, 0xfc, 0xfc, 0xfc, 0xfc, 0xfc, 0xfc, 0xfc, 0xfc, 0xfc, 0xfc, 0xfc, 0xfc, 
	0xfc, 0xfc, 0xfc, 0xfc, 0xfc, 0xfc, 0xfc, 0xfc, 0xfc, 0xfc, 0xfc, 0xfc, 0xfc, 0xfc, 0xfc, 0xfc, 
	0xfc, 0xfc, 0xfc, 0xfc, 0xfc, 0xfc, 0xfc, 0xfc, 0xfc, 0xfc, 0xfc, 0xfc, 0xfc, 0xfc, 0xfc, 0xfc, 
	0xfc, 0xfc, 0xfc, 0xfc, 0xfc, 0xfc, 0xfc, 0xfc, 0xfc, 0xfc, 0xfc, 0xfc, 0xfc, 0xfc, 0xfc, 0xfc, 
	0xfc, 0xfc, 0xfc, 0xfc, 0xfc, 0xfc, 0xfc, 0xfc, 0xfc, 0xfe, 0xfe, 0xff, 0xff, 0xff, 0xff, 0xff, 
	0xff, 0xff, 0xff, 0xff, 0xff, 0xff, 0xff, 0xff, 0xff, 0xff, 0xff, 0xff, 0xff, 0xff, 0xff, 0xf};
```

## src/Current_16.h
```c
uint8_t buf[1024] = {
0xff, 0xff, 0xff, 0xff, 0xff, 0xff, 0xff, 0xff, 0xff, 0xff, 0xff, 0xff, 0xff, 0xff, 0xff, 0xff, 
0xff, 0xff, 0xff, 0xff, 0xff, 0xff, 0xff, 0xff, 0xff, 0xff, 0xff, 0xff, 0xff, 0xff, 0xff, 0xff, 
0xff, 0xff, 0xff, 0xff, 0xff, 0xff, 0xff, 0xff, 0xff, 0xff, 0xff, 0xff, 0xff, 0xff, 0xff, 0xff, 
0xff, 0xff, 0xff, 0xff, 0xff, 0xff, 0xff, 0xff, 0xff, 0xff, 0xff, 0xff, 0xff, 0xff, 0xff, 0xff, 
0xff, 0xff, 0xff, 0xff, 0xff, 0xff, 0xff, 0xff, 0xff, 0xff, 0xff, 0xff, 0xff, 0xff, 0xff, 0xff, 
0xff, 0xff, 0xff, 0xff, 0xff, 0xff, 0xff, 0xff, 0xff, 0xff, 0xff, 0xff, 0xff, 0xff, 0xff, 0xff, 
0xff, 0xff, 0xff, 0xff, 0xff, 0xff, 0xff, 0xff, 0xff, 0xff, 0xff, 0xff, 0xff, 0xff, 0xff, 0xff, 
0xff, 0xff, 0xff, 0xff, 0xff, 0xff, 0xff, 0xff, 0xff, 0xff, 0xff, 0xff, 0xff, 0xff, 0xff, 0xff, 
0xff, 0xff, 0xff, 0xff, 0xff, 0xff, 0xff, 0xff, 0xff, 0xff, 0xff, 0xff, 0xff, 0xff, 0x1f, 0x07, 
0xc3, 0xf1, 0xf9, 0xfc, 0xfc, 0xfc, 0xfc, 0xfc, 0xfc, 0xfc, 0xff, 0xff, 0xff, 0x7f, 0x3f, 0x9f, 
0x9f, 0x9f, 0x9f, 0x9f, 0x3f, 0x7f, 0xff, 0xff, 0xff, 0xff, 0x1f, 0x1f, 0x3f, 0xbf, 0x9f, 0x9f, 
0xff, 0xff, 0x1f, 0x1f, 0x7f, 0x3f, 0x9f, 0x9f, 0xff, 0xff, 0xfd, 0x18, 0x1c, 0xff, 0xff, 0xff, 
0xff, 0x7f, 0x3f, 0x9f, 0x9f, 0xdf, 0x9f, 0x3f, 0x3f, 0xff, 0xff, 0xff, 0xff, 0x1f, 0x1f, 0x3f, 
0xbf, 0x9f, 0x9f, 0x9f, 0x1f, 0x3f, 0x7f, 0xff, 0xff, 0x9f, 0x9f, 0x03, 0x03, 0x9f, 0x9f, 0x9f, 
0xff, 0xff, 0xff, 0x7f, 0x3f, 0xbf, 0x9f, 0xdf, 0x9f, 0x9f, 0x3f, 0x7f, 0xff, 0xff, 0xff, 0xff, 
0xff, 0xff, 0xff, 0xff, 0xff, 0xff, 0xff, 0xff, 0xff, 0xff, 0xff, 0xff, 0xff, 0xff, 0xff, 0xff, 
0xff, 0xff, 0xff, 0xff, 0xff, 0xff, 0xff, 0xff, 0xff, 0xff, 0xff, 0xff, 0xff, 0xff, 0xf0, 0xc0, 
0x8f, 0x1f, 0x3f, 0x7f, 0x7f, 0x7f, 0x7f, 0x7f, 0x7f, 0x7f, 0xff, 0xff, 0xc0, 0x80, 0x1e, 0x7f, 
0x7f, 0x7f, 0x7f, 0x7f, 0x1e, 0x80, 0xc0, 0xff, 0xff, 0xff, 0x00, 0x00, 0xfe, 0xff, 0xff, 0xff, 
0xff, 0xff, 0x00, 0x00, 0xfe, 0xff, 0xff, 0xff, 0xff, 0xff, 0xff, 0x00, 0x00, 0xff, 0xff, 0xff, 
0xc1, 0x80, 0x3b, 0x7b, 0x7b, 0x7b, 0x7b, 0x7b, 0x78, 0xf8, 0xff, 0xff, 0xff, 0x00, 0x00, 0xff, 
0xff, 0xff, 0xff, 0xff, 0xff, 0x00, 0x00, 0xff, 0xff, 0xff, 0xff, 0x80, 0x00, 0x7f, 0x7f, 0x7f, 
0xff, 0xff, 0xc1, 0x80, 0x3b, 0x7b, 0x7b, 0x7b, 0x7b, 0x7b, 0x7b, 0x78, 0xf8, 0xff, 0xff, 0xff, 
0xff, 0xff, 0xff, 0xff, 0xff, 0xff, 0xff, 0xff, 0xff, 0xff, 0xff, 0xff, 0xff, 0xff, 0xff, 0xff, 
0xff, 0xff, 0xff, 0xff, 0xff, 0xff, 0xff, 0xff, 0xff, 0xff, 0xff, 0xff, 0xff, 0xff, 0xff, 0xff, 
0xff, 0xff, 0xff, 0xfe, 0xfe, 0xfe, 0xfe, 0xfe, 0xfe, 0xfe, 0xff, 0xff, 0xff, 0xff, 0xff, 0xfe, 
0xfe, 0xfe, 0xfe, 0xfe, 0xff, 0xff, 0xff, 0xff, 0xff, 0xff, 0xfe, 0xfe, 0xff, 0xff, 0xff, 0xff, 
0xff, 0xff, 0xfe, 0xfe, 0xff, 0xff, 0xff, 0xff, 0xff, 0xff, 0xff, 0xfe, 0xfe, 0xff, 0xff, 0xff, 
0xff, 0xff, 0xff, 0xfe, 0xfe, 0xfe, 0xfe, 0xfe, 0xfe, 0xff, 0xff, 0xff, 0xff, 0xfe, 0xfe, 0xff, 
0xff, 0xff, 0xff, 0xff, 0xff, 0xfe, 0xfe, 0xff, 0xff, 0xff, 0xff, 0xff, 0xfe, 0xfe, 0xfe, 0xfe, 
0xff, 0xff, 0xff, 0xff, 0xff, 0xfe, 0xfe, 0xfe, 0xfe, 0xfe, 0xfe, 0xfe, 0xff, 0xff, 0xff, 0xff, 
0xff, 0xff, 0xff, 0xff, 0xff, 0xff, 0xff, 0xff, 0xff, 0xff, 0xff, 0xff, 0xff, 0xff, 0xff, 0xff, 
0xff, 0xff, 0xff, 0xff, 0xff, 0xff, 0xff, 0xff, 0xff, 0xff, 0xff, 0xff, 0xff, 0xff, 0xff, 0xff, 
0xff, 0xff, 0xff, 0xff, 0xff, 0xff, 0xff, 0xff, 0xff, 0xff, 0xff, 0x7f, 0x3f, 0x1f, 0x0f, 0x87, 
0xc3, 0xe1, 0xf1, 0xfb, 0xff, 0xff, 0xff, 0xff, 0xff, 0xff, 0xff, 0xff, 0xff, 0xf7, 0xf3, 0xf9, 
0x01, 0x01, 0xff, 0xff, 0xff, 0xff, 0xff, 0xff, 0xff, 0x3f, 0x0f, 0xc7, 0xe3, 0x73, 0x79, 0x79, 
0xf9, 0xf9, 0xff, 0xff, 0xff, 0xff, 0xff, 0xff, 0xff, 0x1f, 0x03, 0xf1, 0xe1, 0x03, 0x1f, 0xff, 
0xff, 0xff, 0xff, 0xff, 0xff, 0xff, 0xff, 0xff, 0xff, 0xff, 0xff, 0xff, 0xff, 0xfd, 0xf8, 0xf0, 
0xe1, 0xc3, 0x87, 0x0f, 0x1f, 0x3f, 0x7f, 0xff, 0xff, 0xff, 0xff, 0xff, 0xff, 0xff, 0xff, 0xff, 
0xff, 0xff, 0xff, 0xff, 0xff, 0xff, 0xff, 0xff, 0xff, 0xff, 0xff, 0xff, 0xff, 0xff, 0xff, 0xff, 
0xff, 0xff, 0xff, 0xff, 0xff, 0xff, 0xff, 0xff, 0xff, 0xff, 0xff, 0xff, 0xff, 0xff, 0xff, 0xff, 
0xff, 0xff, 0xff, 0xff, 0xff, 0xff, 0xff, 0xff, 0xff, 0xfd, 0xf8, 0xf0, 0xe0, 0xc0, 0x87, 0x0f, 
0x1f, 0x3f, 0x7f, 0xff, 0xff, 0xff, 0xff, 0xff, 0xff, 0xff, 0xff, 0xff, 0xff, 0xff, 0xff, 0xff, 
0x00, 0x00, 0xff, 0xff, 0xff, 0xff, 0xff, 0xff, 0xc0, 0x00, 0x39, 0x7c, 0xfe, 0xfe, 0xfe, 0xfe, 
0x7c, 0x00, 0x83, 0xff, 0xff, 0xff, 0x3f, 0x07, 0xc0, 0xe0, 0xe7, 0xe7, 0xe7, 0xe7, 0xe0, 0xc0, 
0x07, 0x3f, 0xff, 0xff, 0xff, 0xff, 0xff, 0xff, 0xff, 0xff, 0xff, 0xff, 0xff, 0x7f, 0x3f, 0x1f, 
0x0f, 0x87, 0xc3, 0xe0, 0xf0, 0xf8, 0xfc, 0xfe, 0xff, 0xff, 0xff, 0xff, 0xff, 0xff, 0xff, 0xff, 
0xff, 0xff, 0xff, 0xff, 0xff, 0xff, 0xff, 0xff, 0xff, 0xff, 0xff, 0xff, 0xff, 0xff, 0xff, 0xff, 
0xff, 0xff, 0xff, 0xff, 0xff, 0xff, 0xff, 0xff, 0xff, 0xff, 0xff, 0xff, 0xff, 0xff, 0xff, 0xff, 
0xff, 0xff, 0xff, 0xff, 0xff, 0xff, 0xff, 0xff, 0xff, 0xff, 0xff, 0xff, 0xff, 0xff, 0xff, 0xff, 
0xfe, 0xfc, 0xfc, 0xfe, 0xff, 0xff, 0xff, 0xff, 0xff, 0xff, 0xff, 0xff, 0xff, 0xff, 0xff, 0xff, 
0xfc, 0xfc, 0xff, 0xff, 0xff, 0xff, 0xff, 0xff, 0xff, 0xff, 0xfe, 0xfe, 0xfc, 0xfc, 0xfc, 0xfc, 
0xfe, 0xfe, 0xff, 0xff, 0xff, 0xfd, 0xfc, 0xfe, 0xff, 0xff, 0xff, 0xff, 0xff, 0xff, 0xff, 0xff, 
0xfe, 0xfc, 0xfd, 0xff, 0xff, 0xff, 0xff, 0xff, 0xff, 0xff, 0xff, 0xff, 0xff, 0xff, 0xfe, 0xfe, 
0xff, 0xff, 0xff, 0xff, 0xff, 0xff, 0xff, 0xff, 0xff, 0xff, 0xff, 0xff, 0xff, 0xff, 0xff, 0xff, 
0xff, 0xff, 0xff, 0xff, 0xff, 0xff, 0xff, 0xff, 0xff, 0xff, 0xff, 0xff, 0xff, 0xff, 0xff, 0xff, 
0xff, 0xff, 0xff, 0xff, 0xff, 0xff, 0xff, 0xff, 0xff, 0xff, 0xff, 0xff, 0xff, 0xff, 0xff, 0xff, 
0xff, 0xff, 0xff, 0xff, 0xff, 0xff, 0xff, 0xff, 0xff, 0xff, 0xff, 0xff, 0xff, 0xff, 0xff, 0xff, 
0xff, 0xff, 0xff, 0xff, 0xff, 0xff, 0xff, 0xff, 0xff, 0xff, 0xff, 0xff, 0xff, 0xff, 0xff, 0xff, 
0xff, 0xff, 0xff, 0xff, 0xff, 0xff, 0xff, 0xff, 0xff, 0xff, 0xff, 0xff, 0xff, 0xff, 0xff, 0xff, 
0xff, 0xff, 0xff, 0xff, 0xff, 0xff, 0xff, 0xff, 0xff, 0xff, 0xff, 0xff, 0xff, 0xff, 0xff, 0xff, 
0xff, 0xff, 0xff, 0xff, 0xff, 0xff, 0xff, 0xff, 0xff, 0xff, 0xff, 0xff, 0xff, 0xff, 0xff, 0xff, 
0xff, 0xff, 0xff, 0xff, 0xff, 0xff, 0xff, 0xff, 0xff, 0xff, 0xff, 0xff, 0xff, 0xff, 0xff, 0xff, 
0xff, 0xff, 0xff, 0xff, 0xff, 0xff, 0xff, 0xff, 0xff, 0xff, 0xff, 0xff, 0xff, 0xff, 0xff, 0xff
};
```

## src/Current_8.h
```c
uint8_t buf[1024] = {
0xff, 0xff, 0xff, 0xff, 0xff, 0xff, 0xff, 0xff, 0xff, 0xff, 0xff, 0xff, 0xff, 0xff, 0xff, 0xff, 
0xff, 0xff, 0xff, 0xff, 0xff, 0xff, 0xff, 0xff, 0xff, 0xff, 0xff, 0xff, 0xff, 0xff, 0xff, 0xff, 
0xff, 0xff, 0xff, 0xff, 0xff, 0xff, 0xff, 0xff, 0xff, 0xff, 0xff, 0xff, 0xff, 0xff, 0xff, 0xff, 
0xff, 0xff, 0xff, 0xff, 0xff, 0xff, 0xff, 0xff, 0xff, 0xff, 0xff, 0xff, 0xff, 0xff, 0xff, 0xff, 
0xff, 0xff, 0xff, 0xff, 0xff, 0xff, 0xff, 0xff, 0xff, 0xff, 0xff, 0xff, 0xff, 0xff, 0xff, 0xff, 
0xff, 0xff, 0xff, 0xff, 0xff, 0xff, 0xff, 0xff, 0xff, 0xff, 0xff, 0xff, 0xff, 0xff, 0xff, 0xff, 
0xff, 0xff, 0xff, 0xff, 0xff, 0xff, 0xff, 0xff, 0xff, 0xff, 0xff, 0xff, 0xff, 0xff, 0xff, 0xff, 
0xff, 0xff, 0xff, 0xff, 0xff, 0xff, 0xff, 0xff, 0xff, 0xff, 0xff, 0xff, 0xff, 0xff, 0xff, 0xff, 
0xff, 0xff, 0xff, 0xff, 0xff, 0xff, 0xff, 0xff, 0xff, 0xff, 0xff, 0xff, 0xff, 0xff, 0x1f, 0x07, 
0xc3, 0xf1, 0xf9, 0xfc, 0xfc, 0xfc, 0xfc, 0xfc, 0xfc, 0xfc, 0xff, 0xff, 0xff, 0x7f, 0x3f, 0x9f, 
0x9f, 0x9f, 0x9f, 0x9f, 0x3f, 0x7f, 0xff, 0xff, 0xff, 0xff, 0x1f, 0x1f, 0x3f, 0xbf, 0x9f, 0x9f, 
0xff, 0xff, 0x1f, 0x1f, 0x7f, 0x3f, 0x9f, 0x9f, 0xff, 0xff, 0xfd, 0x18, 0x1c, 0xff, 0xff, 0xff, 
0xff, 0x7f, 0x3f, 0x9f, 0x9f, 0xdf, 0x9f, 0x3f, 0x3f, 0xff, 0xff, 0xff, 0xff, 0x1f, 0x1f, 0x3f, 
0xbf, 0x9f, 0x9f, 0x9f, 0x1f, 0x3f, 0x7f, 0xff, 0xff, 0x9f, 0x9f, 0x03, 0x03, 0x9f, 0x9f, 0x9f, 
0xff, 0xff, 0xff, 0x7f, 0x3f, 0xbf, 0x9f, 0xdf, 0x9f, 0x9f, 0x3f, 0x7f, 0xff, 0xff, 0xff, 0xff, 
0xff, 0xff, 0xff, 0xff, 0xff, 0xff, 0xff, 0xff, 0xff, 0xff, 0xff, 0xff, 0xff, 0xff, 0xff, 0xff, 
0xff, 0xff, 0xff, 0xff, 0xff, 0xff, 0xff, 0xff, 0xff, 0xff, 0xff, 0xff, 0xff, 0xff, 0xf0, 0xc0, 
0x8f, 0x1f, 0x3f, 0x7f, 0x7f, 0x7f, 0x7f, 0x7f, 0x7f, 0x7f, 0xff, 0xff, 0xc0, 0x80, 0x1e, 0x7f, 
0x7f, 0x7f, 0x7f, 0x7f, 0x1e, 0x80, 0xc0, 0xff, 0xff, 0xff, 0x00, 0x00, 0xfe, 0xff, 0xff, 0xff, 
0xff, 0xff, 0x00, 0x00, 0xfe, 0xff, 0xff, 0xff, 0xff, 0xff, 0xff, 0x00, 0x00, 0xff, 0xff, 0xff, 
0xc1, 0x80, 0x3b, 0x7b, 0x7b, 0x7b, 0x7b, 0x7b, 0x78, 0xf8, 0xff, 0xff, 0xff, 0x00, 0x00, 0xff, 
0xff, 0xff, 0xff, 0xff, 0xff, 0x00, 0x00, 0xff, 0xff, 0xff, 0xff, 0x80, 0x00, 0x7f, 0x7f, 0x7f, 
0xff, 0xff, 0xc1, 0x80, 0x3b, 0x7b, 0x7b, 0x7b, 0x7b, 0x7b, 0x7b, 0x78, 0xf8, 0xff, 0xff, 0xff, 
0xff, 0xff, 0xff, 0xff, 0xff, 0xff, 0xff, 0xff, 0xff, 0xff, 0xff, 0xff, 0xff, 0xff, 0xff, 0xff, 
0xff, 0xff, 0xff, 0xff, 0xff, 0xff, 0xff, 0xff, 0xff, 0xff, 0xff, 0xff, 0xff, 0xff, 0xff, 0xff, 
0xff, 0xff, 0xff, 0xfe, 0xfe, 0xfe, 0xfe, 0xfe, 0xfe, 0xfe, 0xff, 0xff, 0xff, 0xff, 0xff, 0xfe, 
0xfe, 0xfe, 0xfe, 0xfe, 0xff, 0xff, 0xff, 0xff, 0xff, 0xff, 0xfe, 0xfe, 0xff, 0xff, 0xff, 0xff, 
0xff, 0xff, 0xfe, 0xfe, 0xff, 0xff, 0xff, 0xff, 0xff, 0xff, 0xff, 0xfe, 0xfe, 0xff, 0xff, 0xff, 
0xff, 0xff, 0xff, 0xfe, 0xfe, 0xfe, 0xfe, 0xfe, 0xfe, 0xff, 0xff, 0xff, 0xff, 0xfe, 0xfe, 0xff, 
0xff, 0xff, 0xff, 0xff, 0xff, 0xfe, 0xfe, 0xff, 0xff, 0xff, 0xff, 0xff, 0xfe, 0xfe, 0xfe, 0xfe, 
0xff, 0xff, 0xff, 0xff, 0xff, 0xfe, 0xfe, 0xfe, 0xfe, 0xfe, 0xfe, 0xfe, 0xff, 0xff, 0xff, 0xff, 
0xff, 0xff, 0xff, 0xff, 0xff, 0xff, 0xff, 0xff, 0xff, 0xff, 0xff, 0xff, 0xff, 0xff, 0xff, 0xff, 
0xff, 0xff, 0xff, 0xff, 0xff, 0xff, 0xff, 0xff, 0xff, 0xff, 0xff, 0xff, 0xff, 0xff, 0xff, 0xff, 
0xff, 0xff, 0xff, 0xff, 0xff, 0xff, 0xff, 0xff, 0xff, 0xff, 0xff, 0xff, 0xff, 0xff, 0xff, 0xff, 
0xff, 0xff, 0xff, 0xff, 0xff, 0xff, 0xff, 0xff, 0xff, 0xff, 0xff, 0xff, 0xff, 0xff, 0xff, 0xff, 
0xff, 0xff, 0x87, 0x03, 0x7b, 0xf9, 0xfd, 0xf9, 0x79, 0x03, 0x87, 0xff, 0xff, 0xff, 0xff, 0xff, 
0xff, 0xff, 0x1f, 0x03, 0xf1, 0xe1, 0x03, 0x1f, 0xff, 0xff, 0xff, 0xff, 0xff, 0xff, 0xff, 0xff, 
0xff, 0xff, 0xff, 0xff, 0xff, 0xff, 0xff, 0xff, 0xff, 0xff, 0xff, 0xff, 0xfd, 0xf8, 0xf0, 0xe1, 
0xc3, 0x87, 0x0f, 0x1f, 0x3f, 0x7f, 0xff, 0xff, 0xff, 0xff, 0xff, 0xff, 0xff, 0xff, 0xff, 0xff, 
0xff, 0xff, 0xff, 0xff, 0xff, 0xff, 0xff, 0xff, 0xff, 0xff, 0xff, 0xff, 0xff, 0xff, 0xff, 0xff, 
0xff, 0xff, 0xff, 0xff, 0xff, 0xff, 0xff, 0xff, 0xff, 0xff, 0xff, 0xff, 0xff, 0xff, 0xff, 0xff, 
0xff, 0xff, 0xff, 0xff, 0xff, 0xff, 0xff, 0xff, 0xff, 0xff, 0xff, 0xff, 0xff, 0xff, 0xff, 0xff, 
0xff, 0xff, 0xff, 0xff, 0xff, 0xff, 0xff, 0xff, 0xff, 0xff, 0xff, 0xff, 0xff, 0xff, 0xff, 0xff, 
0xff, 0x8f, 0x03, 0x73, 0xf8, 0xfc, 0xfc, 0xfc, 0xf8, 0x71, 0x03, 0x87, 0xff, 0xff, 0xff, 0x3f, 
0x07, 0xc0, 0xe0, 0xe7, 0xe7, 0xe7, 0xe7, 0xe0, 0xc0, 0x07, 0x3f, 0xff, 0xff, 0xff, 0xff, 0xff, 
0xff, 0xff, 0xff, 0xff, 0xff, 0xff, 0xff, 0xff, 0xff, 0xff, 0xff, 0xff, 0x7f, 0x3f, 0x1f, 0x0f, 
0x87, 0xc3, 0xe0, 0xf0, 0xf8, 0xfc, 0xfe, 0xff, 0xff, 0xff, 0xff, 0xff, 0xff, 0xff, 0xff, 0xff, 
0xff, 0xff, 0xff, 0xff, 0xff, 0xff, 0xff, 0xff, 0xff, 0xff, 0xff, 0xff, 0xff, 0xff, 0xff, 0xff, 
0xff, 0xff, 0xff, 0xff, 0xff, 0xff, 0xff, 0xff, 0xff, 0xff, 0xff, 0xff, 0xff, 0xff, 0xff, 0xff, 
0xff, 0xff, 0xff, 0xff, 0xff, 0xff, 0xff, 0xff, 0xff, 0xff, 0xff, 0xff, 0xff, 0xff, 0xff, 0xff, 
0xff, 0xff, 0xff, 0xff, 0xff, 0xff, 0xff, 0xff, 0xff, 0xff, 0xff, 0xff, 0xff, 0xff, 0xff, 0xff, 
0xff, 0xff, 0xfe, 0xfe, 0xfc, 0xfc, 0xfc, 0xfc, 0xfc, 0xfe, 0xfe, 0xff, 0xff, 0xff, 0xfd, 0xfc, 
0xfe, 0xff, 0xff, 0xff, 0xff, 0xff, 0xff, 0xff, 0xff, 0xfe, 0xfc, 0xfd, 0xff, 0xff, 0xff, 0xff, 
0xff, 0xff, 0xff, 0xff, 0xff, 0xff, 0xff, 0xff, 0xff, 0xff, 0xff, 0xff, 0xff, 0xfe, 0xfe, 0xff, 
0xff, 0xff, 0xff, 0xff, 0xff, 0xff, 0xff, 0xff, 0xff, 0xff, 0xff, 0xff, 0xff, 0xff, 0xff, 0xff, 
0xff, 0xff, 0xff, 0xff, 0xff, 0xff, 0xff, 0xff, 0xff, 0xff, 0xff, 0xff, 0xff, 0xff, 0xff, 0xff, 
0xff, 0xff, 0xff, 0xff, 0xff, 0xff, 0xff, 0xff, 0xff, 0xff, 0xff, 0xff, 0xff, 0xff, 0xff, 0xff, 
0xff, 0xff, 0xff, 0xff, 0xff, 0xff, 0xff, 0xff, 0xff, 0xff, 0xff, 0xff, 0xff, 0xff, 0xff, 0xff, 
0xff, 0xff, 0xff, 0xff, 0xff, 0xff, 0xff, 0xff, 0xff, 0xff, 0xff, 0xff, 0xff, 0xff, 0xff, 0xff, 
0xff, 0xff, 0xff, 0xff, 0xff, 0xff, 0xff, 0xff, 0xff, 0xff, 0xff, 0xff, 0xff, 0xff, 0xff, 0xff, 
0xff, 0xff, 0xff, 0xff, 0xff, 0xff, 0xff, 0xff, 0xff, 0xff, 0xff, 0xff, 0xff, 0xff, 0xff, 0xff, 
0xff, 0xff, 0xff, 0xff, 0xff, 0xff, 0xff, 0xff, 0xff, 0xff, 0xff, 0xff, 0xff, 0xff, 0xff, 0xff, 
0xff, 0xff, 0xff, 0xff, 0xff, 0xff, 0xff, 0xff, 0xff, 0xff, 0xff, 0xff, 0xff, 0xff, 0xff, 0xff, 
0xff, 0xff, 0xff, 0xff, 0xff, 0xff, 0xff, 0xff, 0xff, 0xff, 0xff, 0xff, 0xff, 0xff, 0xff, 0xff
};
```

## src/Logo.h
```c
uint8_t buf[1024] = {
    0xff, 0xff, 0xff, 0x1f, 0x0f, 0x0f, 0x0f, 0x0f, 0x1f, 0xff, 0xff, 0xff, 0xff, 0xff, 0xff, 0xff, 
0xff, 0xff, 0xff, 0xff, 0xff, 0xff, 0xff, 0xff, 0xff, 0xff, 0xff, 0xff, 0xff, 0xff, 0xff, 0xff, 
0xff, 0xff, 0x0f, 0x0f, 0x0f, 0x0f, 0x0f, 0x0f, 0xff, 0xff, 0xdf, 0x0f, 0x0f, 0x0f, 0x0f, 0x0f, 
0x0f, 0x0f, 0x0f, 0x0f, 0x0f, 0x0f, 0x0f, 0x0f, 0x0f, 0x0f, 0x0f, 0x0f, 0x0f, 0x0f, 0x0f, 0x1f, 
0x1f, 0x1f, 0x1f, 0x1f, 0x3f, 0x3f, 0x7f, 0x7f, 0xff, 0xff, 0xff, 0xff, 0xff, 0xff, 0xff, 0xff, 
0xff, 0xff, 0xff, 0xff, 0xff, 0xff, 0xff, 0xff, 0xff, 0xff, 0xff, 0xff, 0xff, 0xff, 0xff, 0xff, 
0xff, 0xff, 0xff, 0xff, 0xff, 0xff, 0xff, 0xff, 0xff, 0xff, 0xff, 0xff, 0xff, 0xff, 0xff, 0xff, 
0xff, 0xff, 0xff, 0xff, 0xff, 0xff, 0xff, 0xff, 0xff, 0xff, 0xff, 0xff, 0xff, 0xff, 0xff, 0xff, 
0xff, 0xff, 0xff, 0x00, 0x00, 0x00, 0x00, 0x00, 0x00, 0xff, 0xff, 0xff, 0xff, 0xff, 0xff, 0xff, 
0xff, 0xff, 0xff, 0xff, 0xff, 0xff, 0xff, 0xff, 0xff, 0xff, 0xff, 0xff, 0xff, 0xff, 0xff, 0xff, 
0xff, 0xff, 0x00, 0x00, 0x00, 0x00, 0x00, 0x00, 0xff, 0xff, 0xff, 0x00, 0x00, 0x00, 0x00, 0x00, 
0x00, 0x00, 0xc0, 0xe0, 0xf0, 0xf0, 0xf8, 0xfc, 0xfc, 0xfc, 0xfc, 0xfe, 0xfe, 0xfe, 0xfc, 0xfc, 
0xfc, 0xfc, 0xfc, 0xf8, 0xf8, 0xf0, 0xe0, 0xc0, 0x80, 0x01, 0x03, 0x07, 0x0f, 0x3f, 0xff, 0xff, 
0xff, 0xff, 0xff, 0xff, 0xff, 0xff, 0xff, 0xff, 0xff, 0xff, 0xff, 0xff, 0xff, 0xff, 0xff, 0xff, 
0xff, 0xff, 0xff, 0xff, 0xff, 0xff, 0xff, 0xff, 0xff, 0xff, 0xff, 0xff, 0xff, 0xff, 0xff, 0xff, 
0xff, 0xff, 0xff, 0xff, 0xff, 0xff, 0xff, 0xff, 0xff, 0xff, 0xff, 0xff, 0xff, 0xff, 0xff, 0xff, 
0xff, 0xff, 0xff, 0x80, 0x00, 0x00, 0x00, 0x00, 0x00, 0xff, 0xff, 0xff, 0xff, 0xff, 0xff, 0xff, 
0xff, 0xff, 0xff, 0xff, 0xff, 0xff, 0xff, 0xff, 0xff, 0xff, 0xff, 0xff, 0xff, 0xff, 0xff, 0xff, 
0xff, 0xff, 0x00, 0x00, 0x00, 0x00, 0x00, 0x00, 0xff, 0xff, 0xff, 0x00, 0x00, 0x00, 0x00, 0x00, 
0x00, 0xff, 0xff, 0xff, 0xff, 0xff, 0xff, 0xff, 0xff, 0xff, 0xff, 0xff, 0xff, 0xff, 0xff, 0xff, 
0xff, 0xff, 0xff, 0xff, 0xff, 0xff, 0xff, 0xff, 0xff, 0xfc, 0x00, 0x00, 0x00, 0x00, 0x00, 0xff, 
0xff, 0xff, 0xff, 0xff, 0xff, 0xff, 0xff, 0xff, 0xff, 0xff, 0xff, 0xff, 0xff, 0xff, 0xff, 0xff, 
0xff, 0xff, 0xff, 0xff, 0xff, 0xff, 0xff, 0xff, 0xff, 0xff, 0xff, 0xff, 0xff, 0xff, 0xff, 0xff, 
0xff, 0xff, 0xff, 0xff, 0xff, 0xff, 0xff, 0xff, 0xff, 0xff, 0xff, 0xff, 0xff, 0xff, 0xff, 0xff, 
0xff, 0xff, 0xff, 0xff, 0xf8, 0xe0, 0xc0, 0x00, 0x00, 0x01, 0x07, 0x1f, 0x3f, 0x3f, 0x7f, 0x7f, 
0xff, 0xff, 0xff, 0xff, 0xff, 0xff, 0xff, 0xff, 0xff, 0xff, 0xff, 0x7f, 0x7f, 0x3f, 0x1f, 0x0f, 
0x07, 0x01, 0x00, 0x00, 0x00, 0x00, 0x00, 0x00, 0xff, 0xff, 0xff, 0x00, 0x00, 0x00, 0x00, 0x00, 
0x00, 0xff, 0xff, 0xff, 0xff, 0xff, 0xff, 0xff, 0xff, 0xff, 0xff, 0xff, 0xff, 0xff, 0xff, 0xff, 
0xff, 0xff, 0xff, 0xff, 0xff, 0xff, 0xff, 0xff, 0xff, 0xff, 0x00, 0x00, 0x00, 0x00, 0x00, 0xff, 
0xff, 0xff, 0xff, 0xff, 0xff, 0xff, 0xff, 0xff, 0xff, 0xff, 0xff, 0xff, 0xff, 0xff, 0xff, 0xff, 
0xff, 0xff, 0xff, 0xff, 0xff, 0xff, 0xff, 0xff, 0xff, 0xff, 0xff, 0xff, 0xff, 0xff, 0xff, 0xff, 
0xff, 0xff, 0xff, 0xff, 0xff, 0xff, 0xff, 0xff, 0xff, 0xff, 0xff, 0xff, 0xff, 0xff, 0xff, 0xff, 
0xff, 0xff, 0xff, 0xff, 0xff, 0xff, 0xff, 0xff, 0xfe, 0xfc, 0xfc, 0xf8, 0xf8, 0xf0, 0xf0, 0xe0, 
0xe0, 0xe0, 0xe0, 0xe0, 0xe0, 0xe0, 0xe0, 0xe0, 0xe0, 0xe0, 0xe0, 0xe0, 0xe0, 0xe0, 0xe0, 0xe0, 
0xe0, 0xe0, 0xe0, 0xe0, 0xe0, 0xe0, 0xe0, 0xe0, 0xff, 0xff, 0xef, 0xe0, 0xe0, 0xe0, 0xe0, 0xe0, 
0xe0, 0xff, 0xff, 0xff, 0xff, 0xff, 0xff, 0xff, 0xff, 0xff, 0xff, 0xff, 0xff, 0xff, 0xff, 0xff, 
0xff, 0xff, 0xff, 0xff, 0xff, 0xff, 0xff, 0xff, 0xff, 0xff, 0xe0, 0xe0, 0xe0, 0xe0, 0xe0, 0xff, 
0xff, 0xff, 0xff, 0xff, 0xff, 0xff, 0xff, 0xff, 0xff, 0xff, 0xff, 0xff, 0xff, 0xff, 0xff, 0xff, 
0xff, 0xff, 0xff, 0xff, 0xff, 0xff, 0xff, 0xff, 0xff, 0xff, 0xff, 0xff, 0xff, 0xff, 0xff, 0xff, 
0xff, 0xff, 0xff, 0xff, 0xff, 0xff, 0xff, 0xff, 0xff, 0xff, 0xff, 0xff, 0xff, 0xff, 0xff, 0xff, 
0xff, 0xff, 0xff, 0xff, 0xff, 0xff, 0x3f, 0x1f, 0x8f, 0xcf, 0xe7, 0xe7, 0xe7, 0xe7, 0xe7, 0xe7, 
0xe7, 0xff, 0xff, 0xff, 0xff, 0xff, 0xff, 0x7f, 0x0f, 0xc7, 0x87, 0x0f, 0x7f, 0xff, 0xff, 0xff, 
0xff, 0xff, 0xff, 0x07, 0x07, 0xe7, 0xe7, 0xe7, 0xe7, 0xe7, 0xe7, 0xcf, 0x0f, 0x3f, 0xff, 0xff, 
0xff, 0x7f, 0x1f, 0x9f, 0xcf, 0xef, 0xe7, 0xe7, 0xe7, 0xe7, 0xe7, 0xe7, 0xe7, 0xff, 0xff, 0xff, 
0xff, 0xff, 0xff, 0xff, 0x7f, 0x0f, 0xc7, 0x87, 0x0f, 0x7f, 0xff, 0xff, 0xff, 0xff, 0xff, 0xff, 
0x07, 0x07, 0xe7, 0xe7, 0xe7, 0xe7, 0xe7, 0xe7, 0xe7, 0xcf, 0x8f, 0x1f, 0x3f, 0x7f, 0xff, 0xff, 
0xff, 0x3f, 0x1f, 0x8f, 0xcf, 0xe7, 0xe7, 0xe7, 0xe7, 0xe7, 0xcf, 0x8f, 0x1f, 0x3f, 0xff, 0xff, 
0xff, 0xff, 0x07, 0x07, 0xe7, 0xe7, 0xe7, 0xe7, 0xe7, 0xcf, 0x0f, 0x1f, 0xff, 0xff, 0xff, 0xff, 
0xff, 0xff, 0xff, 0xff, 0xff, 0x80, 0x00, 0x7e, 0xff, 0xff, 0xff, 0xff, 0xff, 0xff, 0xff, 0xff, 
0xff, 0xff, 0xff, 0xff, 0xff, 0x1f, 0x03, 0x80, 0x9c, 0x9f, 0x9f, 0x9c, 0x80, 0x03, 0x1f, 0xff, 
0xff, 0xff, 0xff, 0x00, 0x00, 0xe7, 0xe7, 0xe7, 0xe7, 0xe7, 0xc3, 0x01, 0x38, 0xfe, 0xff, 0xff, 
0x81, 0x00, 0x3e, 0xff, 0xff, 0xff, 0xff, 0xff, 0xe7, 0xe7, 0xe7, 0xe7, 0x07, 0x07, 0xff, 0xff, 
0xff, 0xff, 0x1f, 0x03, 0x80, 0x9c, 0x9f, 0x9f, 0x9c, 0x80, 0x03, 0x1f, 0xff, 0xff, 0xff, 0xff, 
0x00, 0x00, 0xff, 0xff, 0xff, 0xff, 0xff, 0xff, 0xff, 0xff, 0xff, 0x3f, 0x00, 0x80, 0xff, 0xff, 
0x81, 0x00, 0x3e, 0xff, 0xff, 0xff, 0xff, 0xff, 0xff, 0xff, 0xff, 0xff, 0x7f, 0x00, 0x80, 0xff, 
0xff, 0xff, 0x00, 0x00, 0xe7, 0xe7, 0xe7, 0xe7, 0xc7, 0x03, 0x18, 0x7c, 0xff, 0xff, 0xff, 0xff, 
0xff, 0xff, 0xff, 0xff, 0xff, 0xff, 0xfe, 0xfc, 0xf8, 0xf9, 0xf3, 0xf3, 0xf3, 0xf3, 0xf3, 0xf3, 
0xf3, 0xff, 0xff, 0xf7, 0xf0, 0xf8, 0xff, 0xff, 0xff, 0xff, 0xff, 0xff, 0xff, 0xff, 0xf8, 0xf0, 
0xf7, 0xff, 0xff, 0xf0, 0xf0, 0xff, 0xff, 0xff, 0xff, 0xff, 0xff, 0xfe, 0xf0, 0xf1, 0xff, 0xff, 
0xff, 0xfe, 0xfc, 0xf8, 0xf9, 0xf3, 0xf3, 0xf3, 0xf3, 0xf3, 0xf3, 0xf3, 0xf8, 0xf8, 0xff, 0xff, 
0xf7, 0xf0, 0xf8, 0xff, 0xff, 0xff, 0xff, 0xff, 0xff, 0xff, 0xff, 0xf8, 0xf0, 0xf7, 0xff, 0xff, 
0xf0, 0xf0, 0xf3, 0xf3, 0xf3, 0xf3, 0xf3, 0xf3, 0xfb, 0xf9, 0xf8, 0xfc, 0xfe, 0xff, 0xff, 0xff, 
0xff, 0xfe, 0xfc, 0xf8, 0xf9, 0xf3, 0xf3, 0xf3, 0xf3, 0xf3, 0xf9, 0xf8, 0xfc, 0xfe, 0xff, 0xff, 
0xff, 0xff, 0xf0, 0xf0, 0xff, 0xff, 0xff, 0xff, 0xff, 0xff, 0xf0, 0xf0, 0xf7, 0xff, 0xff, 0xff
};
```

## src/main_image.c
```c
#include <stdint.h>
#include <zephyr/device.h>
#include <zephyr/kernel.h>
#include <zephyr/drivers/display.h>
#include <zephyr/logging/log.h>

#include "logo_image.h"

#define DISPLAY_BUFFER_PITCH 128

LOG_MODULE_REGISTER(display);

static const struct device *display = DEVICE_DT_GET(DT_NODELABEL(ssd1306));

void main(void)
{
  if (display == NULL) {
    LOG_ERR("device pointer is NULL");
    return;
  }

  if (!device_is_ready(display)) {
    LOG_ERR("display device is not ready");
    return;
  }

  struct display_capabilities capabilities;
  display_get_capabilities(display, &capabilities);

  const uint16_t x_res = capabilities.x_resolution;
  const uint16_t y_res = capabilities.y_resolution;

  LOG_INF("x_resolution: %d", x_res);
  LOG_INF("y_resolution: %d", y_res);
  LOG_INF("supported pixel formats: %d", capabilities.supported_pixel_formats);
  LOG_INF("screen_info: %d", capabilities.screen_info);
  LOG_INF("current_pixel_format: %d", capabilities.current_pixel_format);
  LOG_INF("current_orientation: %d", capabilities.current_orientation);
	 
  const struct display_buffer_descriptor buf_desc = {
    .width = x_res,
    .height = y_res,
    .buf_size = x_res * y_res,
    .pitch = DISPLAY_BUFFER_PITCH
  };

  if (display_write(display, 0, 0, &buf_desc, buf) != 0) {
    LOG_ERR("could not write to display");
  }

  if (display_set_contrast(display, 0) != 0) {
    LOG_ERR("could not set display contrast");
  }
  size_t ms_sleep = 5;

  while (true) {
    // Increase brightness
    for (size_t i = 0; i < 255; i++) {
      display_set_contrast(display, i);
      k_sleep(K_MSEC(ms_sleep));
    }

    // Decrease brightness
    for (size_t i = 255; i > 0; i--) {
      display_set_contrast(display, i);
      k_sleep(K_MSEC(ms_sleep));
    }
  }
}
```
